# Cortex_M7 register map
Vendor: ARM Ltd.; File version: 1.3
Cortex-M7 core descriptions, generated from ARM develloper studio
CPU: CM7 r0p0, little endian, MPU, no FPU, vendor SysTick, 8 interrupt priority bits
Registers are 32-bit, read-write, no defined reset value unless marked. A register's access mark holds for its fields unless they carry their own. Offsets are from the block's base; lines under a group give offsets from that group; [hi:lo] are bit positions; {n}, {i} and the like mark numbered series; 'fields as' and 'values as' point back to an identical list; <NAME> marks a mode.

## Memory map
0xE000E004 NVIC size 0x4EC — Nested Vectored Interrupt Controller registers
0xE000E008 Control size 0xEFC — System Control registers
0xE000E010 SysTick size 0x80 — System Timer registers
0xE000ED00 ID size 0x74 — ID registers
0xE000ED78 Cache size 0x204 — Cache Control
0xE000ED90 MPU size 0x160 — Memory Protection Unit
0xE000EF34 FPE size 0x18 — FP System Control registers
0xE000EF90 ImpDef size 0xC0 — Implementation defined registers

## Cache — Cache Control
Base 0xE000ED78
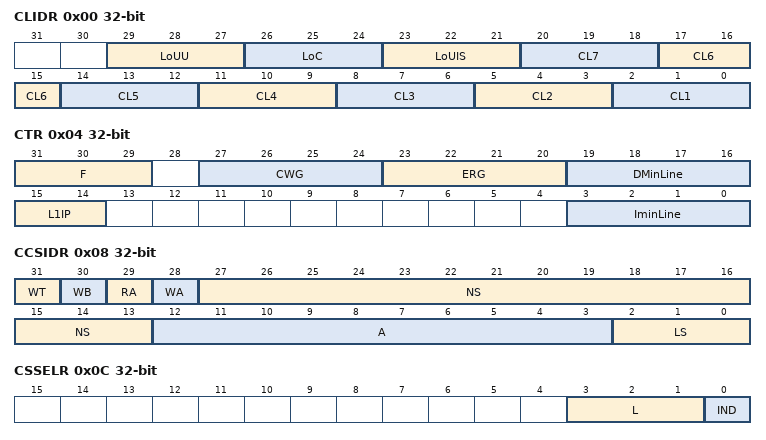
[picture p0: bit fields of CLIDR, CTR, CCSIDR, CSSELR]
0x00 CLIDR ro
  [29:27] LoUU
    0=L1_cache; 1=L2_cache; 2=L3_cache
  [26:24] LoC
    0=L1_cache; 1=L2_cache; 2=L3_cache
  [23:21] LoUIS
    0=L1_cache; 1=L2_cache; 2=L3_cache
  [3n-1:3n-3] CL{n} (n=1..7)
    0=No_cache; 1=I_cache_only; 2=D_cache_only; 3=Separate_I_and_D_caches; 4=Unified_cache
0x04 CTR ro
  [31:29] F
    0=ARMv6_and_earlier_format; 4=ARMv7_format
  [27:24] CWG
    3=_8_word_granularity; 4=_16_word_granularity
  [23:20] ERG
    3=_8_word_granularity; 4=_16_word_granularity
  [19:16] DMinLine
    3=_8_word_granularity; 4=_16_word_granularity
  [15:14] L1IP
    1=Virtual_Index_Virtual_Tag; 2=Virtual_Index_Physical_Tag; 3=Physical_Index_Physical_Tag
  [3:0] IminLine
    3=_8_word_granularity; 4=_16_word_granularity
0x08 CCSIDR ro
  [31] WT
  [30] WB
  [29] RA
  [28] WA
  [27:13] NS
    127=_16KB_cache_size; 255=_32KB_cache_size; 0x1FF=_64KB_cache_size
  [12:3] A
    0=_1_way; {v}=_{v+1}_ways (v=1..15)
  [2:0] LS — Line Size
    0=_4_words; 1=_8_words; 2=_16_words; 3=_32_words; 4=_64_words; 5=_128_words; 6=_256_words; 7=_512_words
0x0C CSSELR
  [3:1] L — Level
  [0] IND — Type
    0=Data_cache; 1=Instruction_cache
0x1D8 ICIALLU wo
0x1E0 ICIMVAU wo
0x1E4 DCIMVAC wo
0x1E8 DCISW wo
0x1EC DCCMVAU wo
0x1F0 DCCMVAC wo
0x1F4 DCCSW wo
0x1F8 DCCIMVAC wo
0x1FC DCCISW wo
0x200 BPIALL wo

## FPE — FP System Control registers
Base 0xE000EF34
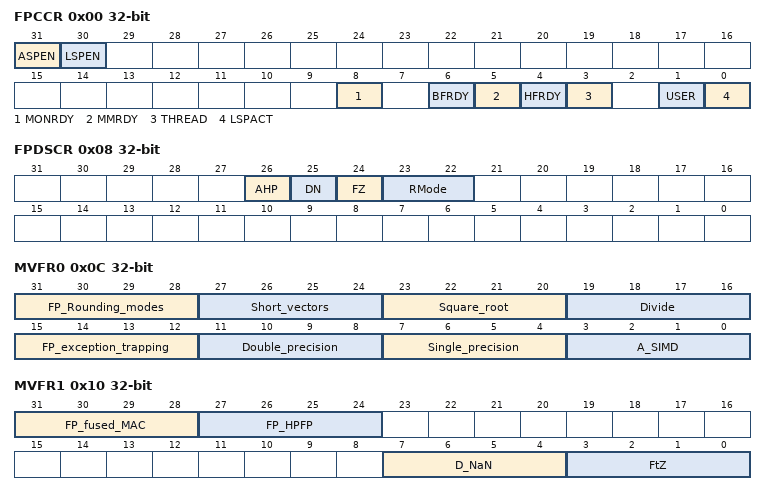
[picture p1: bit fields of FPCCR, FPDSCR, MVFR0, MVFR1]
0x00 FPCCR
  [31] ASPEN
  [30] LSPEN
  [8] MONRDY
    0=Not_Able; 1=Able
  [6] BFRDY
    0=Not_Able; 1=Able
  [5] MMRDY
    0=Not_Able; 1=Able
  [4] HFRDY
    0=Not_Able; 1=Able
  [3] THREAD
    0=Handler; 1=Thread
  [1] USER
    0=Privileged; 1=Unprivileged
  [0] LSPACT
    0=Not_Active; 1=Active
0x04 FPCAR
0x08 FPDSCR
  [26] AHP, [25] DN, [24] FZ, [23:22] RMode
0x0C MVFR0 ro
  [31:28] FP_Rounding_modes
    0=Not_Supported; 1=Supported
  [27:24] Short_vectors
    0=Not_Supported
  [23:20] Square_root
    0=Not_Supported; 1=Supported
  [19:16] Divide
    0=Not_Supported; 1=Supported
  [15:12] FP_exception_trapping
    0=Not_Supported
  [11:8] Double_precision
    0=Not_Supported; 2=Supported
  [7:4] Single_precision
    0=Not_Supported; 2=Supported
  [3:0] A_SIMD
    1=_16x64
0x10 MVFR1 ro
  [31:28] FP_fused_MAC
    0=Not_Supported; 1=Supported
  [27:24] FP_HPFP
    0=Not_Supported; 1=Supported; 2=Supports_conversion_to_double
  [7:4] D_NaN
    0=Not_Supported; 1=Supported
  [3:0] FtZ
    0=Not_Supported; 1=Supported
0x14 MVFR2 ro
  [7:4] VFP_Misc
    0=Not_Supported; 4=Supported

## ID — ID registers
Base 0xE000ED00
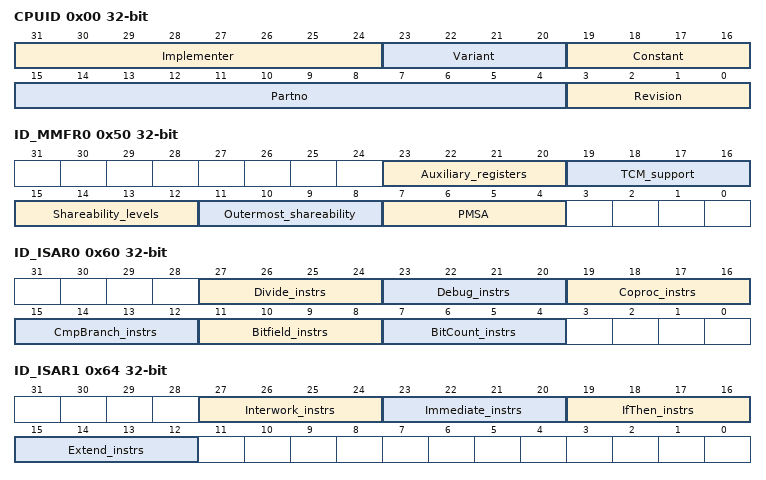
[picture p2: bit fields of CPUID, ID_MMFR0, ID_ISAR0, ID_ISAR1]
0x00 CPUID ro
  [31:24] Implementer, [23:20] Variant, [19:16] Constant, [15:4] Partno, [3:0] Revision
0x40 ID_PFR0 ro
  [7:4] State1
    3=Thumb_Thumb2
0x44 ID_PFR1 ro
  [11:8] M_Profile
    2=Two_stack
0x48 ID_DFR0 ro
  [23:20] M_Profile
    0=Not_supported; 1=Supported
0x4C ID_AFR0 ro
0x50 ID_MMFR0 ro
  [23:20] Auxiliary_registers
    0=Not_supported; 1=Supported
  [19:16] TCM_support
    0=No_TCM; 1=TCM_Implemented
  [15:12] Shareability_levels
    0=One_level
  [11:8] Outermost_shareability
    0=Non_cacheable; 15=Ignored
  [7:4] PMSA
    0=Not_supported; 3=PMSAv7
0x54 ID_MMFR1 ro
0x58 ID_MMFR2 ro
  [27:24] WFI
    0=Not_supported; 1=Supported
0x5C ID_MMFR3 ro
0x60 ID_ISAR0 ro
  [27:24] Divide_instrs
    0=Not_supported; 1=Supported
  [23:20] Debug_instrs
    0=Not_supported; 1=Supported
  [19:16] Coproc_instrs
    0=None; 1=Generic; 2=Generic2; 3=MCRR_MRRC; 4=MCRR2_MRRC2
  [15:12] CmpBranch_instrs
    0=Not_supported; 1=Supported
  [11:8] Bitfield_instrs
    0=Not_supported; 1=Supported
  [7:4] BitCount_instrs
    0=Not_supported; 1=Supported
0x64 ID_ISAR1 ro
  [27:24] Interwork_instrs
    0=None; 1=BX; 2=BX_BLX2
  [23:20] Immediate_instrs
    0=Not_supported; 1=Supported
  [19:16] IfThen_instrs
    0=Not_supported; 1=Supported
  [15:12] Extend_instrs
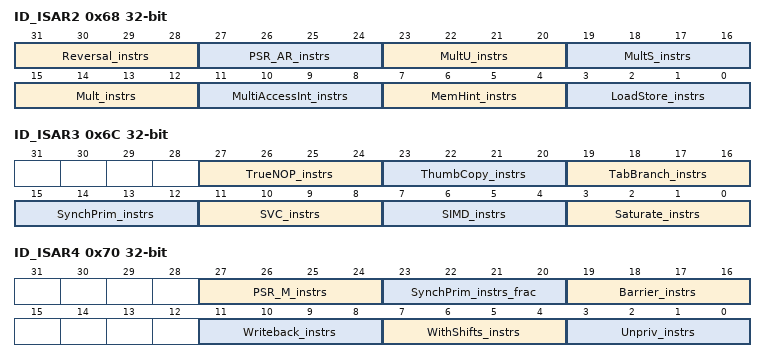
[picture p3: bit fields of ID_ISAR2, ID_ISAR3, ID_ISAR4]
0x68 ID_ISAR2 ro
  [31:28] Reversal_instrs, [27:24] PSR_AR_instrs, [23:20] MultU_instrs, [19:16] MultS_instrs, [15:12] Mult_instrs, [11:8] MultiAccessInt_instrs, [7:4] MemHint_instrs, [3:0] LoadStore_instrs
0x6C ID_ISAR3 ro
  [27:24] TrueNOP_instrs
    0=Not_supported; 1=Supported
  [23:20] ThumbCopy_instrs
    0=Not_supported; 1=Supported
  [19:16] TabBranch_instrs
    0=Not_supported; 1=Supported
  [15:12] SynchPrim_instrs
  [11:8] SVC_instrs
    0=Not_supported; 1=Supported
  [7:4] SIMD_instrs
  [3:0] Saturate_instrs
    0=Not_supported; 1=Supported
0x70 ID_ISAR4 ro
  [27:24] PSR_M_instrs
    0=Not_supported; 1=Supported
  [23:20] SynchPrim_instrs_frac
  [19:16] Barrier_instrs
    0=Not_supported; 1=Supported
  [11:8] Writeback_instrs
    0=Basic; 1=Full
  [7:4] WithShifts_instrs
  [3:0] Unpriv_instrs

## Notices in the file
Copyright (c) 2024 STMicroelectronics.
SPDX-License-Identifier: Apache-2.0
Licensed under the Apache License, Version 2.0 (the "License");
you may not use this file except in compliance with the License.
You may obtain a copy of the License at
http://www.apache.org/licenses/LICENSE-2.0
Unless required by applicable law or agreed to in writing, software
distributed under the License is distributed on an "AS IS" BASIS,
WITHOUT WARRANTIES OR CONDITIONS OF ANY KIND, either express or implied.
See the License for the specific language governing permissions and
limitations under the License.
